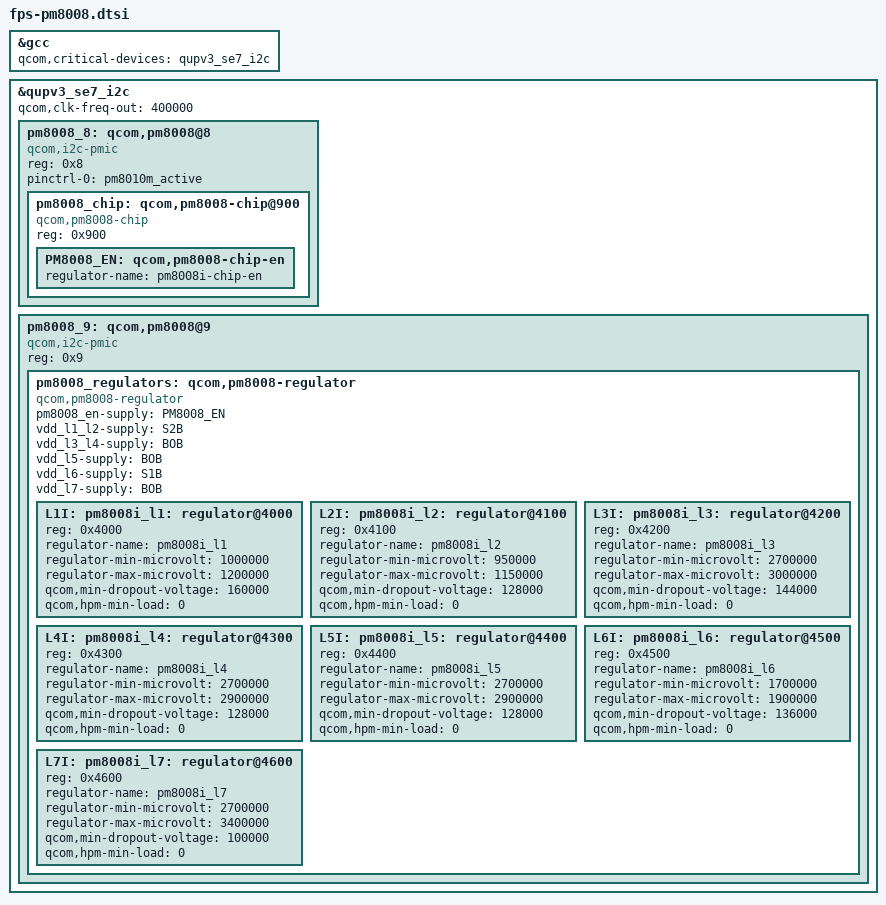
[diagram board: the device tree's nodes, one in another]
#include <dt-bindings/gpio/gpio.h>
#include <dt-bindings/clock/qcom,rpmh.h>

//#include "pmr735b.dtsi"
/*
&pmr735b_gpios {
	pm8008_reset {
		pm8008_active: pm8008_active {
			pins = "gpio3";
			function = "normal";
			bias-disable;
			output-high;
			power-source = <1>;
		};
	};

};

&tlmm {
	pm8008_active: pm8008_active {
		mux {
			pins = "gpio125";
			function = "gpio";
		};

		config {
			pins = "gpio125";
			bias-pull-up;
			output-high;
			drive-strength = <2>;
		};
	};
};

*/

/*
 * Each QUP device that's a parent to PMIC must be listed as a critical device
 * to GCC
 */
&gcc {
	qcom,critical-devices = <&qupv3_se7_i2c>;
};

&qupv3_se7_i2c {
	#address-cells = <1>;
	#size-cells = <0>;
	status = "ok";
	qcom,clk-freq-out = <400000>;//if not set frenquency to 400kHz will cause write reigster fail.

	pm8008_8: qcom,pm8008@8 {
		compatible = "qcom,i2c-pmic";
		reg = <0x8>;
		#address-cells = <1>;
		#size-cells = <0>;

		pinctrl-names = "default";
		pinctrl-0 = <&pm8010m_active>;

		pm8008_chip: qcom,pm8008-chip@900 {
			compatible = "qcom,pm8008-chip";
			reg = <0x900>;

			PM8008_EN: qcom,pm8008-chip-en {
				regulator-name = "pm8008i-chip-en";
			};
		};
	};

	pm8008_9: qcom,pm8008@9 {
		compatible = "qcom,i2c-pmic";
		reg = <0x9>;
		#address-cells = <1>;
		#size-cells = <0>;

		pm8008_regulators: qcom,pm8008-regulator {
			compatible = "qcom,pm8008-regulator";
			#address-cells = <1>;
			#size-cells = <0>;

			pm8008_en-supply = <&PM8008_EN>;
			vdd_l1_l2-supply = <&S2B>;
			vdd_l3_l4-supply = <&BOB>;
			vdd_l5-supply = <&BOB>;
			vdd_l6-supply = <&S1B>;
			vdd_l7-supply = <&BOB>;

			L1I: pm8008i_l1: regulator@4000 {
				reg = <0x4000>;
				regulator-name = "pm8008i_l1";
				regulator-min-microvolt = <1000000>;
				regulator-max-microvolt = <1200000>;
				qcom,min-dropout-voltage = <160000>;
				qcom,hpm-min-load = <0>;
			};

			L2I: pm8008i_l2: regulator@4100 {
				reg = <0x4100>;
				regulator-name = "pm8008i_l2";
				regulator-min-microvolt = <950000>;
				regulator-max-microvolt = <1150000>;
				qcom,min-dropout-voltage = <128000>;
				qcom,hpm-min-load = <0>;
			};

			L3I: pm8008i_l3: regulator@4200 {
				reg = <0x4200>;
				regulator-name = "pm8008i_l3";
				regulator-min-microvolt = <2700000>;
				regulator-max-microvolt = <3000000>;
				qcom,min-dropout-voltage = <144000>;
				qcom,hpm-min-load = <0>;
			};

			L4I: pm8008i_l4: regulator@4300 {
				reg = <0x4300>;
				regulator-name = "pm8008i_l4";
				regulator-min-microvolt = <2700000>;
				regulator-max-microvolt = <2900000>;
				qcom,min-dropout-voltage = <128000>;
				qcom,hpm-min-load = <0>;
			};

			L5I: pm8008i_l5: regulator@4400 {
				reg = <0x4400>;
				regulator-name = "pm8008i_l5";
				regulator-min-microvolt = <2700000>;
				regulator-max-microvolt = <2900000>;
				qcom,min-dropout-voltage = <128000>;
				qcom,hpm-min-load = <0>;
			};

			L6I: pm8008i_l6: regulator@4500 {
				reg = <0x4500>;
				regulator-name = "pm8008i_l6";
				regulator-min-microvolt = <1700000>;
				regulator-max-microvolt = <1900000>;
				qcom,min-dropout-voltage = <136000>;
				qcom,hpm-min-load = <0>;
			};

			L7I: pm8008i_l7: regulator@4600 {
				reg = <0x4600>;
				regulator-name = "pm8008i_l7";
				regulator-min-microvolt = <2700000>;
				regulator-max-microvolt = <3400000>;
				qcom,min-dropout-voltage = <100000>;
				qcom,hpm-min-load = <0>;
			};
		};
	};
};

